# PY32F032xx register map
Vendor: Puya; Series: PY32F0; File version: 1.0.0
CPU: CM0+ r0p1, little endian, no MPU, no FPU, 4 interrupt priority bits
Registers are 32-bit, read-write, reset 0x0 unless marked. A register's access mark holds for its fields unless they carry their own. Offsets are from the block's base; [hi:lo] are bit positions.

## UART1
Base 0x40004800
Same registers: UART2 0x40004C00
0x00 DR
  [8:0] DR — Receive/send data register
0x04 BRR
  [15:0] BRR — Baud rate register
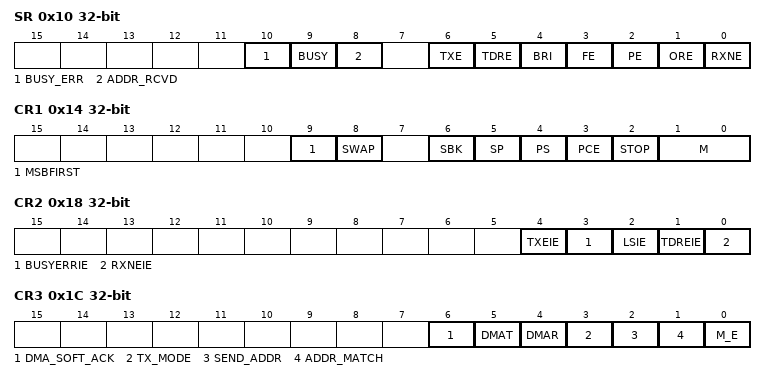
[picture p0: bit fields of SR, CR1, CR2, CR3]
0x10 SR
  [10] BUSY_ERR — Busy Detect Error
  [9] BUSY ro — UART Busy
  [8] ADDR_RCVD — Address Received Bit
  [6] TXE ro — Transmitter Empty bit
  [5] TDRE ro — Transmit Holding Register Empty bit
  [4] BRI — Break Interrupt bit
  [3] FE — Framing Error bit
  [2] PE — Parity Error bit
  [1] ORE — Overrun error bit
  [0] RXNE ro — Receive register not empty
0x14 CR1
  [9] MSBFIRST — MSB first mode
  [8] SWAP — TX/RX pin swap
  [6] SBK — Send Break
  [5] SP — Stick Parity
  [4] PS — Even Parity Select
  [3] PCE — Parity Enable
  [2] STOP — Number of stop bits
  [1:0] M — Data Length Select
0x18 CR2
  [4] TXEIE — Enable tx empty interruption
  [3] BUSYERRIE — Enable Busyerr state interruption
  [2] LSIE — Enable Receiver Line Status Interrupt
  [1] TDREIE — Enable Transmit Holding Register Empty Interrupt
  [0] RXNEIE — Enable Received Data Available Interrupt
0x1C CR3
  [6] DMA_SOFT_ACK — DMA software ack
  [5] DMAT — DMA transmit enable
  [4] DMAR — DMA receive enable
  [3] TX_MODE — Transmit mode control bit
  [2] SEND_ADDR — Send address control bit
  [1] ADDR_MATCH — Address Match Mode
  [0] M_E — Extension for DLS
0x20 RAR
  [7:0] RAR — Receive address matching register
0x24 TAR
  [7:0] TAR — Transmit address matching register
0x28 BRRF
  [3:0] BRRF — Baud rate fractional register

## USART1 — Universal synchronous asynchronous receivertransmitter
Base 0x40013800
Same registers: USART2 0x40004400
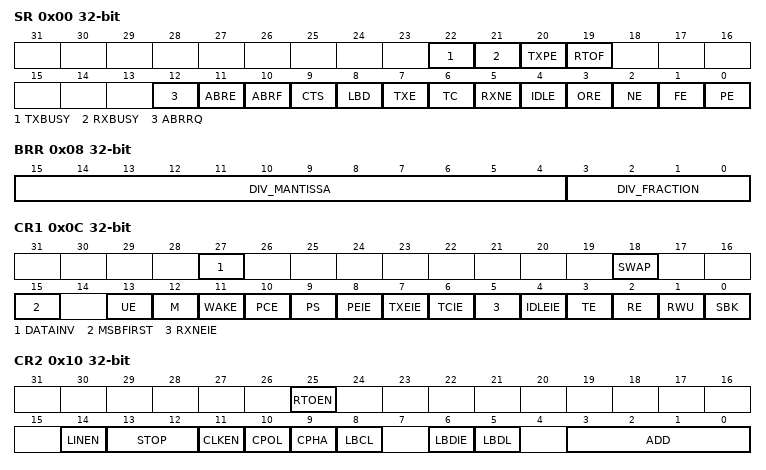
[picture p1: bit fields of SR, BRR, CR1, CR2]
0x00 SR — Status register
  [22] TXBUSY ro
  [21] RXBUSY ro
  [20] TXPE
  [19] RTOF — rto flag
  [12] ABRRQ ro — auto baud rate req
  [11] ABRE ro — auto baud rateerror
  [10] ABRF ro — auto baud rate flag
  [9] CTS — cts flag
  [8] LBD — LIN break detection flag
  [7] TXE ro — Transmit data register empty
  [6] TC — Transmission complete
  [5] RXNE — Read data register not empty
  [4] IDLE ro
  [3] ORE ro — overrun error
  [2] NE ro — Noise error flag
  [1] FE ro — Framing error
  [0] PE ro — Parity error
0x04 DR — Data register
  [8:0] DR
0x08 BRR — Baud rate register
  [15:4] DIV_MANTISSA, [3:0] DIV_FRACTION
0x0C CR1 — Control register 1
  [27] DATAINV — data inverse
  [18] SWAP
  [15] MSBFIRST
  [13] UE — uesart enable
  [12] M — word length
  [11] WAKE — Wakeup method
  [10] PCE — Parity control enable
  [9] PS — Parity selection
  [8] PEIE — PE interrupt enable
  [7] TXEIE — txe
  [6] TCIE — send complete int enable
  [5] RXNEIE — RXNE interrupt enable
  [4] IDLEIE — IDLE interrupt enable
  [3] TE — Transmitter enable
  [2] RE — Receiver enable
  [1] RWU — Receiver wakeup
  [0] SBK — Send break
0x10 CR2 — Control register 2
  [25] RTOEN — Receiver timeout enable
  [14] LINEN — lin enable
  [13:12] STOP — stop bit
  [11] CLKEN
  [10] CPOL
  [9] CPHA
  [8] LBCL
  [6] LBDIE — lin break enable
  [5] LBDL — LIN break detection length
  [3:0] ADD — mute addr
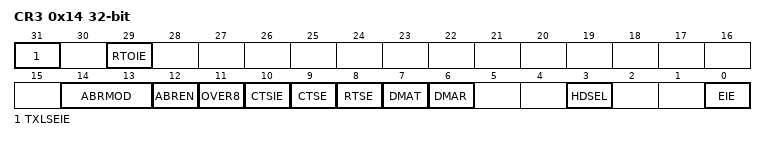
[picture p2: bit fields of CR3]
0x14 CR3 — Control register 3
  [31] TXLSEIE — tx register empty int enable
  [29] RTOIE — rto int enable
  [14:13] ABRMOD — auto baud mod
  [12] ABREN — autobaud enable
  [11] OVER8 — oversampling
  [10] CTSIE — cts int enable
  [9] CTSE — cts enable
  [8] RTSE — rts enable
  [7] DMAT — dma tx enable
  [6] DMAR — dma rx enable
  [3] HDSEL
  [0] EIE — error int enable
0x1C RTOR
  [23:0] RTO — receive timeout

## WWDG — Window watchdog
Base 0x40002C00
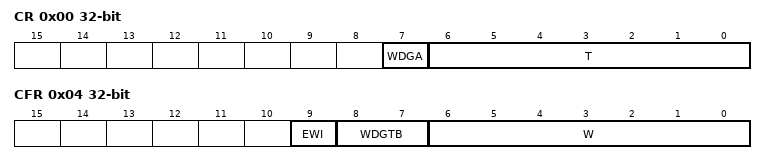
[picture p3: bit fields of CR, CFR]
0x00 CR — Control register (WWDG_CR)
  [7] WDGA — WWDG Activation
  [6:0] T — wwdg counter bit
0x04 CFR — Configuration register(WWDG_CFR)
  [9] EWI — Early wakeup interrupt
  [8:7] WDGTB — time base bit
  [6:0] W — window value bit
0x08 SR — Status register (WWDG_SR)
  [0] EWIF — Early wakeup interrupt flag
